VERSION ""

NS_ :

BS_:

BU_:

BO_ 3221225472 VECTOR__INDEPENDENT_SIG_MSG: 0 Vector__XXX
 SG_ NewSignal_0008 : 47|8@0+ (1,0) [0|0] "" Vector__XXX
 SG_ NewSignal_0001 : 47|8@0+ (1,0) [0|0] "" Vector__XXX
 SG_ STATUS : 47|8@0+ (1,0) [0|0] "" Vector__XXX

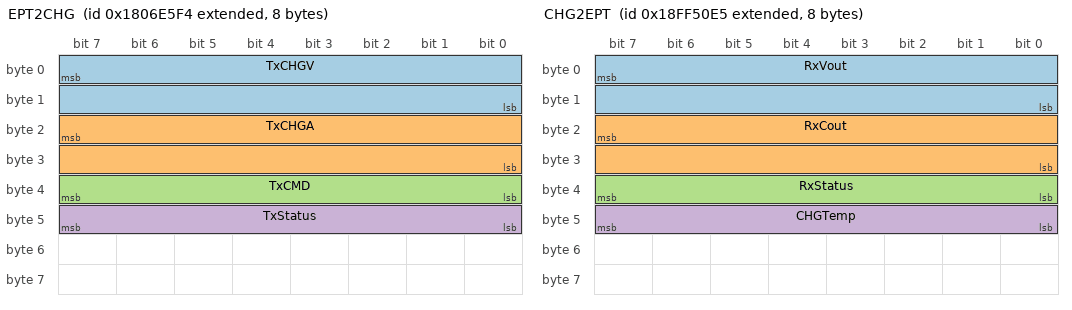
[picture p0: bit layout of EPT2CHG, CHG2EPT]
BO_ 2550588916 EPT2CHG: 8 Vector__XXX
 SG_ TxCHGV : 7|16@0+ (0.1,0) [70|132] "V" Vector__XXX
 SG_ TxCHGA : 23|16@0+ (0.1,0) [0|35] "A" Vector__XXX
 SG_ TxCMD : 39|8@0+ (1,0) [0|0] "" Vector__XXX
 SG_ TxStatus : 47|8@0+ (1,0) [0|0] "" Vector__XXX

BO_ 2566869221 CHG2EPT: 8 Vector__XXX
 SG_ RxVout : 7|16@0+ (0.1,0) [0|0] "V" Vector__XXX
 SG_ RxCout : 23|16@0+ (0.1,0) [0|0] "A" Vector__XXX
 SG_ RxStatus : 39|8@0+ (1,0) [0|0] "" Vector__XXX
 SG_ CHGTemp : 47|8@0+ (1,-40) [0|0] "C" Vector__XXX
